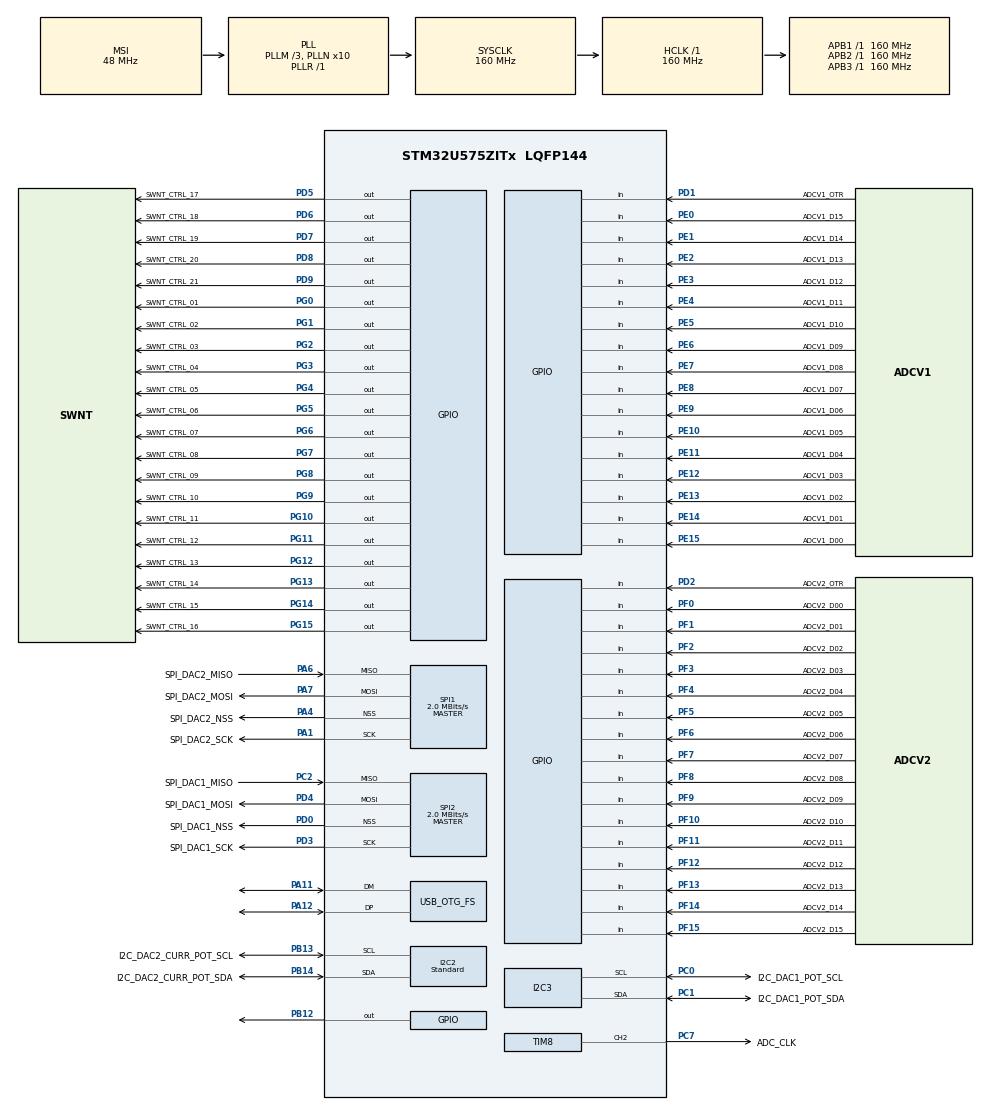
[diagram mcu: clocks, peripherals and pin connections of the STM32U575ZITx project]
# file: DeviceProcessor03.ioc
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CORTEX_M33_NS.userName=CORTEX_M33
GPDMA1.CIRCULARMODE_GPDMACH13=DISABLE
GPDMA1.DESTDATAWIDTH_GPDMACH12=DMA_DEST_DATAWIDTH_HALFWORD
GPDMA1.DESTDATAWIDTH_GPDMACH13=DMA_DEST_DATAWIDTH_HALFWORD
GPDMA1.DESTDATAWIDTH_GPDMACH14=DMA_DEST_DATAWIDTH_HALFWORD
GPDMA1.DESTINC_GPDMACH12=DMA_DINC_INCREMENTED
GPDMA1.DESTINC_GPDMACH13=DMA_DINC_INCREMENTED
GPDMA1.DESTINC_GPDMACH14=DMA_DINC_INCREMENTED
GPDMA1.DIRECTION_GPDMACH12=DMA_PERIPH_TO_MEMORY
GPDMA1.DIRECTION_GPDMACH13=DMA_PERIPH_TO_MEMORY
GPDMA1.DIRECTION_GPDMACH14=DMA_MEMORY_TO_MEMORY
GPDMA1.IPHANDLE_GPDMACH12-SIMPLEREQUEST_GPDMACH12=__NULL
GPDMA1.IPHANDLE_GPDMACH13-SIMPLEREQUEST_GPDMACH13=__NULL
GPDMA1.IPHANDLE_GPDMACH14-SIMPLEREQUEST_GPDMACH14=__NULL
GPDMA1.PRIORITY_GPDMACH12=DMA_LOW_PRIORITY_HIGH_WEIGHT
GPDMA1.PRIORITY_GPDMACH14=DMA_LOW_PRIORITY_HIGH_WEIGHT
GPDMA1.REQUEST_GPDMACH12=GPDMA1_REQUEST_TIM8_UP
GPDMA1.REQUEST_GPDMACH13=GPDMA1_REQUEST_TIM8_UP
GPDMA1.REQUEST_GPDMACH14=GPDMA1_REQUEST_TIM8_UP
GPDMA1.SRCDATAWIDTH_GPDMACH12=DMA_SRC_DATAWIDTH_HALFWORD
GPDMA1.SRCDATAWIDTH_GPDMACH13=DMA_SRC_DATAWIDTH_HALFWORD
GPDMA1.SRCDATAWIDTH_GPDMACH14=DMA_SRC_DATAWIDTH_HALFWORD
GPDMA1.SRCINC_GPDMACH13=DMA_SINC_FIXED
GPDMA1.TRIGGERPOLARITY_GPDMACH12=DMA_TRIG_POLARITY_MASKED
GPDMA1.TRIGGERPOLARITY_GPDMACH13=DMA_TRIG_POLARITY_MASKED
GPDMA1.TRIGGERPOLARITY_GPDMACH14=DMA_TRIG_POLARITY_MASKED
I2C2.I2C_Speed_Mode=I2C_Standard
I2C2.Timing=0x00000E14
I2C3.Timing=0x00000E14
Mcu.Family=STM32U5
Mcu.Name=STM32U575ZITx
Mcu.Package=LQFP144
NVIC.GPDMA1_Channel12_IRQn=true\:0\:0\:false\:false\:true\:false\:true\:true
NVIC.GPDMA1_Channel13_IRQn=true\:0\:0\:false\:false\:true\:false\:true\:true
NVIC.GPDMA1_Channel14_IRQn=true\:0\:0\:false\:false\:true\:false\:true\:true
NVIC.OTG_FS_IRQn=true\:0\:0\:false\:false\:true\:true\:true\:true
NVIC.PriorityGroup=NVIC_PRIORITYGROUP_4
NVIC.TIM8_UP_IRQn=true\:0\:0\:false\:false\:true\:true\:true\:true
PA1.GPIO_Label=SPI_DAC2_SCK
PA1.Mode=Full_Duplex_Master
PA1.Signal=SPI1_SCK
PA11.Mode=Device_Only
PA11.Signal=USB_OTG_FS_DM
PA12.Mode=Device_Only
PA12.Signal=USB_OTG_FS_DP
PA4.GPIO_Label=SPI_DAC2_NSS
PA4.Mode=NSS_Signal_Hard_Output
PA4.Signal=SPI1_NSS
PA6.GPIO_Label=SPI_DAC2_MISO
PA6.Mode=Full_Duplex_Master
PA6.Signal=SPI1_MISO
PA7.GPIO_Label=SPI_DAC2_MOSI
PA7.Mode=Full_Duplex_Master
PA7.Signal=SPI1_MOSI
PB12.Signal=GPIO_Output
PB13.GPIO_Label=I2C_DAC2_CURR_POT_SCL
PB13.GPIO_Pu=GPIO_PULLUP
PB13.GPIO_Speed=GPIO_SPEED_FREQ_VERY_HIGH
PB13.Mode=I2C
PB13.Signal=I2C2_SCL
PB14.GPIO_Label=I2C_DAC2_CURR_POT_SDA
PB14.GPIO_Pu=GPIO_PULLUP
PB14.GPIO_Speed=GPIO_SPEED_FREQ_VERY_HIGH
PB14.Mode=I2C
PB14.Signal=I2C2_SDA
PC0.GPIO_Label=I2C_DAC1_POT_SCL
PC0.GPIO_Pu=GPIO_PULLUP
PC0.GPIO_Speed=GPIO_SPEED_FREQ_VERY_HIGH
PC0.Mode=I2C
PC0.Signal=I2C3_SCL
PC1.GPIO_Label=I2C_DAC1_POT_SDA
PC1.GPIO_Pu=GPIO_PULLUP
PC1.GPIO_Speed=GPIO_SPEED_FREQ_VERY_HIGH
PC1.Mode=I2C
PC1.Signal=I2C3_SDA
PC2.GPIO_Label=SPI_DAC1_MISO
PC2.Mode=Full_Duplex_Master
PC2.Signal=SPI2_MISO
PC7.GPIO_Label=ADC_CLK
PC7.GPIO_Speed=GPIO_SPEED_FREQ_VERY_HIGH
PC7.Signal=S_TIM8_CH2
PD0.GPIO_Label=SPI_DAC1_NSS
PD0.Mode=NSS_Signal_Hard_Output
PD0.Signal=SPI2_NSS
PD1.GPIO_Label=ADCV1_OTR
PD1.Signal=GPIO_Input
PD2.GPIO_Label=ADCV2_OTR
PD2.Signal=GPIO_Input
PD3.GPIO_Label=SPI_DAC1_SCK
PD3.Mode=Full_Duplex_Master
PD3.Signal=SPI2_SCK
PD4.GPIO_Label=SPI_DAC1_MOSI
PD4.Mode=Full_Duplex_Master
PD4.Signal=SPI2_MOSI
PD5.GPIO_Label=SWNT_CTRL_17
PD5.Signal=GPIO_Output
PD6.GPIO_Label=SWNT_CTRL_18
PD6.GPIO_PuPd=GPIO_NOPULL
PD6.Signal=GPIO_Output
PD7.GPIO_Label=SWNT_CTRL_19
PD7.Signal=GPIO_Output
PD8.GPIO_Label=SWNT_CTRL_20
PD8.Signal=GPIO_Output
PD9.GPIO_Label=SWNT_CTRL_21
PD9.Signal=GPIO_Output
PE0.GPIO_Label=ADCV1_D15
PE0.GPIO_PuPd=GPIO_PULLDOWN
PE0.Signal=GPIO_Input
PE1.GPIO_Label=ADCV1_D14
PE1.GPIO_PuPd=GPIO_PULLDOWN
PE1.Signal=GPIO_Input
PE10.GPIO_Label=ADCV1_D05
PE10.Signal=GPIO_Input
PE11.GPIO_Label=ADCV1_D04
PE11.Signal=GPIO_Input
PE12.GPIO_Label=ADCV1_D03
PE12.Signal=GPIO_Input
PE13.GPIO_Label=ADCV1_D02
PE13.Signal=GPIO_Input
PE14.GPIO_Label=ADCV1_D01
PE14.Signal=GPIO_Input
PE15.GPIO_Label=ADCV1_D00
PE15.Signal=GPIO_Input
PE2.GPIO_Label=ADCV1_D13
PE2.GPIO_PuPd=GPIO_PULLDOWN
PE2.Signal=GPIO_Input
PE3.GPIO_Label=ADCV1_D12
PE3.GPIO_PuPd=GPIO_PULLDOWN
PE3.Signal=GPIO_Input
PE4.GPIO_Label=ADCV1_D11
PE4.Signal=GPIO_Input
PE5.GPIO_Label=ADCV1_D10
PE5.Signal=GPIO_Input
PE6.GPIO_Label=ADCV1_D09
PE6.Signal=GPIO_Input
PE7.GPIO_Label=ADCV1_D08
PE7.Signal=GPIO_Input
PE8.GPIO_Label=ADCV1_D07
PE8.Signal=GPIO_Input
PE9.GPIO_Label=ADCV1_D06
PE9.Signal=GPIO_Input
PF0.GPIO_Label=ADCV2_D00
PF0.Signal=GPIO_Input
PF1.GPIO_Label=ADCV2_D01
PF1.Signal=GPIO_Input
PF10.GPIO_Label=ADCV2_D10
PF10.Signal=GPIO_Input
PF11.GPIO_Label=ADCV2_D11
PF11.Signal=GPIO_Input
PF12.GPIO_Label=ADCV2_D12
PF12.GPIO_PuPd=GPIO_PULLDOWN
PF12.Signal=GPIO_Input
PF13.GPIO_Label=ADCV2_D13
PF13.GPIO_PuPd=GPIO_PULLDOWN
PF13.Signal=GPIO_Input
PF14.GPIO_Label=ADCV2_D14
PF14.GPIO_PuPd=GPIO_PULLDOWN
PF14.Signal=GPIO_Input
PF15.GPIO_Label=ADCV2_D15
PF15.GPIO_PuPd=GPIO_PULLDOWN
PF15.Signal=GPIO_Input
PF2.GPIO_Label=ADCV2_D02
PF2.Signal=GPIO_Input
PF3.GPIO_Label=ADCV2_D03
PF3.Signal=GPIO_Input
PF4.GPIO_Label=ADCV2_D04
PF4.Signal=GPIO_Input
PF5.GPIO_Label=ADCV2_D05
PF5.Signal=GPIO_Input
PF6.GPIO_Label=ADCV2_D06
PF6.Signal=GPIO_Input
PF7.GPIO_Label=ADCV2_D07
PF7.Signal=GPIO_Input
PF8.GPIO_Label=ADCV2_D08
PF8.Signal=GPIO_Input
PF9.GPIO_Label=ADCV2_D09
PF9.Signal=GPIO_Input
PG0.GPIO_Label=SWNT_CTRL_01
PG0.Signal=GPIO_Output
PG1.GPIO_Label=SWNT_CTRL_02
PG1.Signal=GPIO_Output
PG10.GPIO_Label=SWNT_CTRL_11
PG10.Signal=GPIO_Output
PG11.GPIO_Label=SWNT_CTRL_12
PG11.Signal=GPIO_Output
PG12.GPIO_Label=SWNT_CTRL_13
PG12.Signal=GPIO_Output
PG13.GPIO_Label=SWNT_CTRL_14
PG13.Signal=GPIO_Output
PG14.GPIO_Label=SWNT_CTRL_15
PG14.Signal=GPIO_Output
PG15.GPIO_Label=SWNT_CTRL_16
PG15.Signal=GPIO_Output
PG2.GPIO_Label=SWNT_CTRL_03
PG2.Signal=GPIO_Output
PG3.GPIO_Label=SWNT_CTRL_04
PG3.Signal=GPIO_Output
PG4.GPIO_Label=SWNT_CTRL_05
PG4.Signal=GPIO_Output
PG5.GPIO_Label=SWNT_CTRL_06
PG5.Signal=GPIO_Output
PG6.GPIO_Label=SWNT_CTRL_07
PG6.Signal=GPIO_Output
PG7.GPIO_Label=SWNT_CTRL_08
PG7.Signal=GPIO_Output
PG8.GPIO_Label=SWNT_CTRL_09
PG8.Signal=GPIO_Output
PG9.GPIO_Label=SWNT_CTRL_10
PG9.Signal=GPIO_Output
ProjectManager.HeapSize=0x200
ProjectManager.StackSize=0x400
ProjectManager.TargetToolchain=STM32CubeIDE
RCC.ADCFreq_Value=16000000
RCC.AHBFreq_Value=160000000
RCC.APB1Freq_Value=160000000
RCC.APB1TimFreq_Value=160000000
RCC.APB2Freq_Value=160000000
RCC.APB2TimFreq_Value=160000000
RCC.APB3Freq_Value=160000000
RCC.CortexFreq_Value=160000000
RCC.EPOD_VALUE=48000000
RCC.HCLKFreq_Value=160000000
RCC.HSE_VALUE=16000000
RCC.HSI48_VALUE=48000000
RCC.HSI_VALUE=16000000
RCC.I2C2CLockSelection=RCC_I2C2CLKSOURCE_MSIK
RCC.I2C3CLockSelection=RCC_I2C3CLKSOURCE_MSIK
RCC.LSE_VALUE=32768
RCC.LSIDIV_VALUE=32000
RCC.MSIClockRange=RCC_MSIRANGE_0
RCC.MSI_VALUE=48000000
RCC.PLL1R=1
RCC.PLL2FRACN=0
RCC.PLL3FRACN=0
RCC.PLLFRACN=0
RCC.PLLM=3
RCC.PLLN=10
RCC.SPI1CLockSelection=RCC_SPI1CLKSOURCE_MSIK
RCC.SPI2CLockSelection=RCC_SPI2CLKSOURCE_MSIK
RCC.SYSCLKFreq_VALUE=160000000
RCC.SYSCLKSource=RCC_SYSCLKSOURCE_PLLCLK
RCC.USBFreq_Value=48000000
RCC.VCOOutputFreq_Value=160000000
SH.S_TIM8_CH2.0=TIM8_CH2,PWM Generation2 CH2
SPI1.CLKPolarity=SPI_POLARITY_HIGH
SPI1.CalculateBaudRate=2.0 MBits/s
SPI1.DataSize=SPI_DATASIZE_8BIT
SPI1.Direction=SPI_DIRECTION_2LINES
SPI1.Mode=SPI_MODE_MASTER
SPI1.VirtualNSS=VM_NSSHARD
SPI1.VirtualType=VM_MASTER
SPI2.CLKPolarity=SPI_POLARITY_HIGH
SPI2.CalculateBaudRate=2.0 MBits/s
SPI2.DataSize=SPI_DATASIZE_8BIT
SPI2.Direction=SPI_DIRECTION_2LINES
SPI2.Mode=SPI_MODE_MASTER
SPI2.VirtualNSS=VM_NSSHARD
SPI2.VirtualType=VM_MASTER
TIM8.AutoReloadPreload=TIM_AUTORELOAD_PRELOAD_ENABLE
TIM8.Channel-PWM\ Generation2\ CH2=TIM_CHANNEL_2
TIM8.PeriodNoDither=15
TIM8.TIM_MasterOutputTrigger=TIM_TRGO_UPDATE
USB_OTG_FS.VirtualMode=Device_Only
VP_GPDMA1_VS_GPDMACH12.Mode=SIMPLEREQUEST_GPDMACH12
VP_GPDMA1_VS_GPDMACH13.Mode=SIMPLEREQUEST_GPDMACH13
VP_GPDMA1_VS_GPDMACH14.Mode=SIMPLEREQUEST_GPDMACH14
VP_ICACHE_VS_ENABLE_ICACHE_MEMORY.Mode=Memoryregions
VP_ICACHE_VS_ICACHE.Mode=DirectMappedCache
VP_LPBAMQUEUE_VS_QUEUE.Mode=QUEUEMODE
VP_LPBAM_VS_SIG1.Mode=SmartRun
VP_LPBAM_VS_SIG4.Mode=LPDMA1
VP_MEMORYMAP_VS_MEMORYMAP.Mode=CurAppReg
VP_PWR_VS_SECSignals.Mode=Security/Privilege
VP_TIM8_VS_ClockSourceINT.Mode=Internal
board=custom

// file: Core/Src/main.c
/* USER CODE BEGIN Header */
/**
  ******************************************************************************
  * @file           : main.c
  * @brief          : Main program body
  ******************************************************************************
  * @attention
  *
  * Copyright (c) 2025 STMicroelectronics.
  * All rights reserved.
  *
  * This software is licensed under terms that can be found in the LICENSE file
  * in the root directory of this software component.
  * If no LICENSE file comes with this software, it is provided AS-IS.
  *
  ******************************************************************************
  */
/* USER CODE END Header */
#include "main.h"

/* USER CODE BEGIN Includes */
#include "usb_device.h"
#include "device_registers.h"
#include "run_device.h"
/* USER CODE END Includes */

DMA_HandleTypeDef handle_GPDMA1_Channel14;
DMA_HandleTypeDef handle_GPDMA1_Channel12;

I2C_HandleTypeDef hi2c2;
I2C_HandleTypeDef hi2c3;

SPI_HandleTypeDef hspi1;
SPI_HandleTypeDef hspi2;

TIM_HandleTypeDef htim8;
DMA_HandleTypeDef handle_GPDMA1_Channel13;

PCD_HandleTypeDef hpcd_USB_OTG_FS;

void SystemClock_Config(void);
static void MX_GPIO_Init(void);
static void MX_GPDMA1_Init(void);
static void MX_USB_OTG_FS_PCD_Init(void);
static void MX_ICACHE_Init(void);
static void MX_TIM8_Init(void);
static void MX_I2C2_Init(void);
static void MX_I2C3_Init(void);
static void MX_SPI2_Init(void);
static void MX_SPI1_Init(void);

/* USER CODE BEGIN 0 */
uint8_t I2C_TX_Buffer1[] = {0,126};
uint8_t I2C_TX_Buffer2[] = {0,15};
uint8_t I2C_TX_Buffer3[] = {0,30};
uint8_t I2C_TX_Buffer4[] = {0,15};
uint8_t SPI_TX_Buffer1[] = {0x21,0x00,0x50,0xC7,0x40,0x00,0xC0,0x00,0x20,0x00};  // 400Hz
uint8_t SPI_TX_Buffer2[] = {0x21,0x00,0x61,0x8E,0x40,0x00,0xC0,0x00,0x20,0x00};  // 800Hz
uint8_t SPI_TX_Buffer3[] = {0x21,0x00,0x63,0x6E,0x40,0x06,0xC0,0x00,0x20,0x00};  // 10kHz
uint8_t SPI_TX_Buffer4[] = {0x21,0x00,0x6B,0x85,0x41,0x47,0xC0,0x00,0x20,0x00};  // 0.5MHz
uint8_t SPI_TX_Buffer5[] = {0x21,0x00,0x59,0x9A,0x46,0x66,0xC0,0x00,0x20,0x00};  // 2.5MHz
uint8_t SPI_TX_Buffer6[] = {0x21,0x00,0x66,0x66,0x59,0x99,0xC0,0x00,0x20,0x00};  // 10MHz
/* USER CODE END 0 */

int main(void)
{

  /* MCU Configuration--------------------------------------------------------*/

  /* Reset of all peripherals, Initializes the Flash interface and the Systick. */
  HAL_Init();

  /* Configure the system clock */
  SystemClock_Config();

  /* Initialize all configured peripherals */
  MX_GPIO_Init();
  MX_GPDMA1_Init();
  MX_USB_OTG_FS_PCD_Init();
  MX_ICACHE_Init();
  MX_TIM8_Init();
  MX_I2C2_Init();
  MX_I2C3_Init();
  MX_SPI2_Init();
  MX_SPI1_Init();
  /* USER CODE BEGIN 2 */
  MX_USB_Device_Init();
  HAL_Delay(2000);
  run_device();
  /* USER CODE END 2 */

  /* Infinite loop */
  while (1)
  {

  }
}

void SystemClock_Config(void)
{
  RCC_OscInitTypeDef RCC_OscInitStruct = {0};
  RCC_ClkInitTypeDef RCC_ClkInitStruct = {0};

  /** Configure the main internal regulator output voltage
  */
  if (HAL_PWREx_ControlVoltageScaling(PWR_REGULATOR_VOLTAGE_SCALE1) != HAL_OK)
  {
    Error_Handler();
  }

  /** Initializes the CPU, AHB and APB buses clocks
  */
  RCC_OscInitStruct.OscillatorType = RCC_OSCILLATORTYPE_HSI48|RCC_OSCILLATORTYPE_MSI
                              |RCC_OSCILLATORTYPE_MSIK;
  RCC_OscInitStruct.HSI48State = RCC_HSI48_ON;
  RCC_OscInitStruct.MSIState = RCC_MSI_ON;
  RCC_OscInitStruct.MSICalibrationValue = RCC_MSICALIBRATION_DEFAULT;
  RCC_OscInitStruct.MSIClockRange = RCC_MSIRANGE_0;
  RCC_OscInitStruct.MSIKClockRange = RCC_MSIKRANGE_4;
  RCC_OscInitStruct.MSIKState = RCC_MSIK_ON;
  RCC_OscInitStruct.PLL.PLLState = RCC_PLL_ON;
  RCC_OscInitStruct.PLL.PLLSource = RCC_PLLSOURCE_MSI;
  RCC_OscInitStruct.PLL.PLLMBOOST = RCC_PLLMBOOST_DIV4;
  RCC_OscInitStruct.PLL.PLLM = 3;
  RCC_OscInitStruct.PLL.PLLN = 10;
  RCC_OscInitStruct.PLL.PLLP = 2;
  RCC_OscInitStruct.PLL.PLLQ = 2;
  RCC_OscInitStruct.PLL.PLLR = 1;
  RCC_OscInitStruct.PLL.PLLRGE = RCC_PLLVCIRANGE_1;
  RCC_OscInitStruct.PLL.PLLFRACN = 0;
  if (HAL_RCC_OscConfig(&RCC_OscInitStruct) != HAL_OK)
  {
    Error_Handler();
  }

  /** Initializes the CPU, AHB and APB buses clocks
  */
  RCC_ClkInitStruct.ClockType = RCC_CLOCKTYPE_HCLK|RCC_CLOCKTYPE_SYSCLK
                              |RCC_CLOCKTYPE_PCLK1|RCC_CLOCKTYPE_PCLK2
                              |RCC_CLOCKTYPE_PCLK3;
  RCC_ClkInitStruct.SYSCLKSource = RCC_SYSCLKSOURCE_PLLCLK;
  RCC_ClkInitStruct.AHBCLKDivider = RCC_SYSCLK_DIV1;
  RCC_ClkInitStruct.APB1CLKDivider = RCC_HCLK_DIV1;
  RCC_ClkInitStruct.APB2CLKDivider = RCC_HCLK_DIV1;
  RCC_ClkInitStruct.APB3CLKDivider = RCC_HCLK_DIV1;

  if (HAL_RCC_ClockConfig(&RCC_ClkInitStruct, FLASH_LATENCY_4) != HAL_OK)
  {
    Error_Handler();
  }
}

static void MX_GPDMA1_Init(void)
{

  /* Peripheral clock enable */
  __HAL_RCC_GPDMA1_CLK_ENABLE();

  /* GPDMA1 interrupt Init */
    HAL_NVIC_SetPriority(GPDMA1_Channel13_IRQn, 0, 0);
    HAL_NVIC_EnableIRQ(GPDMA1_Channel13_IRQn);

  handle_GPDMA1_Channel14.Instance = GPDMA1_Channel14;
  handle_GPDMA1_Channel14.Init.Request = DMA_REQUEST_SW;
  handle_GPDMA1_Channel14.Init.BlkHWRequest = DMA_BREQ_SINGLE_BURST;
  handle_GPDMA1_Channel14.Init.Direction = DMA_MEMORY_TO_MEMORY;
  handle_GPDMA1_Channel14.Init.SrcInc = DMA_SINC_FIXED;
  handle_GPDMA1_Channel14.Init.DestInc = DMA_DINC_FIXED;
  handle_GPDMA1_Channel14.Init.SrcDataWidth = DMA_SRC_DATAWIDTH_BYTE;
  handle_GPDMA1_Channel14.Init.DestDataWidth = DMA_DEST_DATAWIDTH_BYTE;
  handle_GPDMA1_Channel14.Init.Priority = DMA_LOW_PRIORITY_LOW_WEIGHT;
  handle_GPDMA1_Channel14.Init.SrcBurstLength = 1;
  handle_GPDMA1_Channel14.Init.DestBurstLength = 1;
  handle_GPDMA1_Channel14.Init.TransferAllocatedPort = DMA_SRC_ALLOCATED_PORT0|DMA_DEST_ALLOCATED_PORT0;
  handle_GPDMA1_Channel14.Init.TransferEventMode = DMA_TCEM_BLOCK_TRANSFER;
  handle_GPDMA1_Channel14.Init.Mode = DMA_NORMAL;
  if (HAL_DMA_Init(&handle_GPDMA1_Channel14) != HAL_OK)
  {
    Error_Handler();
  }
  if (HAL_DMA_ConfigChannelAttributes(&handle_GPDMA1_Channel14, DMA_CHANNEL_NPRIV) != HAL_OK)
  {
    Error_Handler();
  }
  handle_GPDMA1_Channel12.Instance = GPDMA1_Channel12;
  handle_GPDMA1_Channel12.Init.Request = DMA_REQUEST_SW;
  handle_GPDMA1_Channel12.Init.BlkHWRequest = DMA_BREQ_SINGLE_BURST;
  handle_GPDMA1_Channel12.Init.Direction = DMA_MEMORY_TO_MEMORY;
  handle_GPDMA1_Channel12.Init.SrcInc = DMA_SINC_FIXED;
  handle_GPDMA1_Channel12.Init.DestInc = DMA_DINC_FIXED;
  handle_GPDMA1_Channel12.Init.SrcDataWidth = DMA_SRC_DATAWIDTH_BYTE;
  handle_GPDMA1_Channel12.Init.DestDataWidth = DMA_DEST_DATAWIDTH_BYTE;
  handle_GPDMA1_Channel12.Init.Priority = DMA_LOW_PRIORITY_LOW_WEIGHT;
  handle_GPDMA1_Channel12.Init.SrcBurstLength = 1;
  handle_GPDMA1_Channel12.Init.DestBurstLength = 1;
  handle_GPDMA1_Channel12.Init.TransferAllocatedPort = DMA_SRC_ALLOCATED_PORT0|DMA_DEST_ALLOCATED_PORT0;
  handle_GPDMA1_Channel12.Init.TransferEventMode = DMA_TCEM_BLOCK_TRANSFER;
  handle_GPDMA1_Channel12.Init.Mode = DMA_NORMAL;
  if (HAL_DMA_Init(&handle_GPDMA1_Channel12) != HAL_OK)
  {
    Error_Handler();
  }
  if (HAL_DMA_ConfigChannelAttributes(&handle_GPDMA1_Channel12, DMA_CHANNEL_NPRIV) != HAL_OK)
  {
    Error_Handler();
  }

}

static void MX_I2C2_Init(void)
{

  hi2c2.Instance = I2C2;
  hi2c2.Init.Timing = 0x00000E14;
  hi2c2.Init.OwnAddress1 = 0;
  hi2c2.Init.AddressingMode = I2C_ADDRESSINGMODE_7BIT;
  hi2c2.Init.DualAddressMode = I2C_DUALADDRESS_DISABLE;
  hi2c2.Init.OwnAddress2 = 0;
  hi2c2.Init.OwnAddress2Masks = I2C_OA2_NOMASK;
  hi2c2.Init.GeneralCallMode = I2C_GENERALCALL_DISABLE;
  hi2c2.Init.NoStretchMode = I2C_NOSTRETCH_DISABLE;
  if (HAL_I2C_Init(&hi2c2) != HAL_OK)
  {
    Error_Handler();
  }

  /** Configure Analogue filter
  */
  if (HAL_I2CEx_ConfigAnalogFilter(&hi2c2, I2C_ANALOGFILTER_ENABLE) != HAL_OK)
  {
    Error_Handler();
  }

  /** Configure Digital filter
  */
  if (HAL_I2CEx_ConfigDigitalFilter(&hi2c2, 0) != HAL_OK)
  {
    Error_Handler();
  }

}

static void MX_I2C3_Init(void)
{

  hi2c3.Instance = I2C3;
  hi2c3.Init.Timing = 0x00000E14;
  hi2c3.Init.OwnAddress1 = 0;
  hi2c3.Init.AddressingMode = I2C_ADDRESSINGMODE_7BIT;
  hi2c3.Init.DualAddressMode = I2C_DUALADDRESS_DISABLE;
  hi2c3.Init.OwnAddress2 = 0;
  hi2c3.Init.OwnAddress2Masks = I2C_OA2_NOMASK;
  hi2c3.Init.GeneralCallMode = I2C_GENERALCALL_DISABLE;
  hi2c3.Init.NoStretchMode = I2C_NOSTRETCH_DISABLE;
  if (HAL_I2C_Init(&hi2c3) != HAL_OK)
  {
    Error_Handler();
  }

  /** Configure Analogue filter
  */
  if (HAL_I2CEx_ConfigAnalogFilter(&hi2c3, I2C_ANALOGFILTER_ENABLE) != HAL_OK)
  {
    Error_Handler();
  }

  /** Configure Digital filter
  */
  if (HAL_I2CEx_ConfigDigitalFilter(&hi2c3, 0) != HAL_OK)
  {
    Error_Handler();
  }

}

static void MX_ICACHE_Init(void)
{

  /** Enable instruction cache in 1-way (direct mapped cache)
  */
  if (HAL_ICACHE_ConfigAssociativityMode(ICACHE_1WAY) != HAL_OK)
  {
    Error_Handler();
  }
  if (HAL_ICACHE_Enable() != HAL_OK)
  {
    Error_Handler();
  }

}

static void MX_SPI1_Init(void)
{

  SPI_AutonomousModeConfTypeDef HAL_SPI_AutonomousMode_Cfg_Struct = {0};

  /* SPI1 parameter configuration*/
  hspi1.Instance = SPI1;
  hspi1.Init.Mode = SPI_MODE_MASTER;
  hspi1.Init.Direction = SPI_DIRECTION_2LINES;
  hspi1.Init.DataSize = SPI_DATASIZE_8BIT;
  hspi1.Init.CLKPolarity = SPI_POLARITY_HIGH;
  hspi1.Init.CLKPhase = SPI_PHASE_1EDGE;
  hspi1.Init.NSS = SPI_NSS_HARD_OUTPUT;
  hspi1.Init.BaudRatePrescaler = SPI_BAUDRATEPRESCALER_2;
  hspi1.Init.FirstBit = SPI_FIRSTBIT_MSB;
  hspi1.Init.TIMode = SPI_TIMODE_DISABLE;
  hspi1.Init.CRCCalculation = SPI_CRCCALCULATION_DISABLE;
  hspi1.Init.CRCPolynomial = 0x7;
  hspi1.Init.NSSPMode = SPI_NSS_PULSE_ENABLE;
  hspi1.Init.NSSPolarity = SPI_NSS_POLARITY_LOW;
  hspi1.Init.FifoThreshold = SPI_FIFO_THRESHOLD_01DATA;
  hspi1.Init.MasterSSIdleness = SPI_MASTER_SS_IDLENESS_00CYCLE;
  hspi1.Init.MasterInterDataIdleness = SPI_MASTER_INTERDATA_IDLENESS_00CYCLE;
  hspi1.Init.MasterReceiverAutoSusp = SPI_MASTER_RX_AUTOSUSP_DISABLE;
  hspi1.Init.MasterKeepIOState = SPI_MASTER_KEEP_IO_STATE_DISABLE;
  hspi1.Init.IOSwap = SPI_IO_SWAP_DISABLE;
  hspi1.Init.ReadyMasterManagement = SPI_RDY_MASTER_MANAGEMENT_INTERNALLY;
  hspi1.Init.ReadyPolarity = SPI_RDY_POLARITY_HIGH;
  if (HAL_SPI_Init(&hspi1) != HAL_OK)
  {
    Error_Handler();
  }
  HAL_SPI_AutonomousMode_Cfg_Struct.TriggerState = SPI_AUTO_MODE_DISABLE;
  HAL_SPI_AutonomousMode_Cfg_Struct.TriggerSelection = SPI_GRP1_GPDMA_CH0_TCF_TRG;
  HAL_SPI_AutonomousMode_Cfg_Struct.TriggerPolarity = SPI_TRIG_POLARITY_RISING;
  if (HAL_SPIEx_SetConfigAutonomousMode(&hspi1, &HAL_SPI_AutonomousMode_Cfg_Struct) != HAL_OK)
  {
    Error_Handler();
  }

}

static void MX_SPI2_Init(void)
{

  SPI_AutonomousModeConfTypeDef HAL_SPI_AutonomousMode_Cfg_Struct = {0};

  /* SPI2 parameter configuration*/
  hspi2.Instance = SPI2;
  hspi2.Init.Mode = SPI_MODE_MASTER;
  hspi2.Init.Direction = SPI_DIRECTION_2LINES;
  hspi2.Init.DataSize = SPI_DATASIZE_8BIT;
  hspi2.Init.CLKPolarity = SPI_POLARITY_HIGH;
  hspi2.Init.CLKPhase = SPI_PHASE_1EDGE;
  hspi2.Init.NSS = SPI_NSS_HARD_OUTPUT;
  hspi2.Init.BaudRatePrescaler = SPI_BAUDRATEPRESCALER_2;
  hspi2.Init.FirstBit = SPI_FIRSTBIT_MSB;
  hspi2.Init.TIMode = SPI_TIMODE_DISABLE;
  hspi2.Init.CRCCalculation = SPI_CRCCALCULATION_DISABLE;
  hspi2.Init.CRCPolynomial = 0x7;
  hspi2.Init.NSSPMode = SPI_NSS_PULSE_ENABLE;
  hspi2.Init.NSSPolarity = SPI_NSS_POLARITY_LOW;
  hspi2.Init.FifoThreshold = SPI_FIFO_THRESHOLD_01DATA;
  hspi2.Init.MasterSSIdleness = SPI_MASTER_SS_IDLENESS_00CYCLE;
  hspi2.Init.MasterInterDataIdleness = SPI_MASTER_INTERDATA_IDLENESS_00CYCLE;
  hspi2.Init.MasterReceiverAutoSusp = SPI_MASTER_RX_AUTOSUSP_DISABLE;
  hspi2.Init.MasterKeepIOState = SPI_MASTER_KEEP_IO_STATE_DISABLE;
  hspi2.Init.IOSwap = SPI_IO_SWAP_DISABLE;
  hspi2.Init.ReadyMasterManagement = SPI_RDY_MASTER_MANAGEMENT_INTERNALLY;
  hspi2.Init.ReadyPolarity = SPI_RDY_POLARITY_HIGH;
  if (HAL_SPI_Init(&hspi2) != HAL_OK)
  {
    Error_Handler();
  }
  HAL_SPI_AutonomousMode_Cfg_Struct.TriggerState = SPI_AUTO_MODE_DISABLE;
  HAL_SPI_AutonomousMode_Cfg_Struct.TriggerSelection = SPI_GRP1_GPDMA_CH0_TCF_TRG;
  HAL_SPI_AutonomousMode_Cfg_Struct.TriggerPolarity = SPI_TRIG_POLARITY_RISING;
  if (HAL_SPIEx_SetConfigAutonomousMode(&hspi2, &HAL_SPI_AutonomousMode_Cfg_Struct) != HAL_OK)
  {
    Error_Handler();
  }

}

static void MX_TIM8_Init(void)
{

  TIM_ClockConfigTypeDef sClockSourceConfig = {0};
  TIM_MasterConfigTypeDef sMasterConfig = {0};
  TIM_OC_InitTypeDef sConfigOC = {0};
  TIM_BreakDeadTimeConfigTypeDef sBreakDeadTimeConfig = {0};

  htim8.Instance = TIM8;
  htim8.Init.Prescaler = 0;
  htim8.Init.CounterMode = TIM_COUNTERMODE_UP;
  htim8.Init.Period = 65535;
  htim8.Init.ClockDivision = TIM_CLOCKDIVISION_DIV1;
  htim8.Init.RepetitionCounter = 0;
  htim8.Init.AutoReloadPreload = TIM_AUTORELOAD_PRELOAD_ENABLE;
  if (HAL_TIM_Base_Init(&htim8) != HAL_OK)
  {
    Error_Handler();
  }
  sClockSourceConfig.ClockSource = TIM_CLOCKSOURCE_INTERNAL;
  if (HAL_TIM_ConfigClockSource(&htim8, &sClockSourceConfig) != HAL_OK)
  {
    Error_Handler();
  }
  if (HAL_TIM_PWM_Init(&htim8) != HAL_OK)
  {
    Error_Handler();
  }
  sMasterConfig.MasterOutputTrigger = TIM_TRGO_UPDATE;
  sMasterConfig.MasterOutputTrigger2 = TIM_TRGO2_RESET;
  sMasterConfig.MasterSlaveMode = TIM_MASTERSLAVEMODE_DISABLE;
  if (HAL_TIMEx_MasterConfigSynchronization(&htim8, &sMasterConfig) != HAL_OK)
  {
    Error_Handler();
  }
  sConfigOC.OCMode = TIM_OCMODE_PWM1;
  sConfigOC.Pulse = 0;
  sConfigOC.OCPolarity = TIM_OCPOLARITY_HIGH;
  sConfigOC.OCNPolarity = TIM_OCNPOLARITY_HIGH;
  sConfigOC.OCFastMode = TIM_OCFAST_DISABLE;
  sConfigOC.OCIdleState = TIM_OCIDLESTATE_RESET;
  sConfigOC.OCNIdleState = TIM_OCNIDLESTATE_RESET;
  if (HAL_TIM_PWM_ConfigChannel(&htim8, &sConfigOC, TIM_CHANNEL_2) != HAL_OK)
  {
    Error_Handler();
  }
  sBreakDeadTimeConfig.OffStateRunMode = TIM_OSSR_DISABLE;
  sBreakDeadTimeConfig.OffStateIDLEMode = TIM_OSSI_DISABLE;
  sBreakDeadTimeConfig.LockLevel = TIM_LOCKLEVEL_OFF;
  sBreakDeadTimeConfig.DeadTime = 0;
  sBreakDeadTimeConfig.BreakState = TIM_BREAK_DISABLE;
  sBreakDeadTimeConfig.BreakPolarity = TIM_BREAKPOLARITY_HIGH;
  sBreakDeadTimeConfig.BreakFilter = 0;
  sBreakDeadTimeConfig.BreakAFMode = TIM_BREAK_AFMODE_INPUT;
  sBreakDeadTimeConfig.Break2State = TIM_BREAK2_DISABLE;
  sBreakDeadTimeConfig.Break2Polarity = TIM_BREAK2POLARITY_HIGH;
  sBreakDeadTimeConfig.Break2Filter = 0;
  sBreakDeadTimeConfig.Break2AFMode = TIM_BREAK_AFMODE_INPUT;
  sBreakDeadTimeConfig.AutomaticOutput = TIM_AUTOMATICOUTPUT_DISABLE;
  if (HAL_TIMEx_ConfigBreakDeadTime(&htim8, &sBreakDeadTimeConfig) != HAL_OK)
  {
    Error_Handler();
  }
  HAL_TIM_MspPostInit(&htim8);

}

static void MX_USB_OTG_FS_PCD_Init(void)
{

  hpcd_USB_OTG_FS.Instance = USB_OTG_FS;
  hpcd_USB_OTG_FS.Init.dev_endpoints = 6;
  hpcd_USB_OTG_FS.Init.speed = PCD_SPEED_FULL;
  hpcd_USB_OTG_FS.Init.phy_itface = PCD_PHY_EMBEDDED;
  hpcd_USB_OTG_FS.Init.Sof_enable = DISABLE;
  hpcd_USB_OTG_FS.Init.low_power_enable = DISABLE;
  hpcd_USB_OTG_FS.Init.lpm_enable = DISABLE;
  hpcd_USB_OTG_FS.Init.battery_charging_enable = DISABLE;
  hpcd_USB_OTG_FS.Init.use_dedicated_ep1 = DISABLE;
  hpcd_USB_OTG_FS.Init.vbus_sensing_enable = DISABLE;
  hpcd_USB_OTG_FS.Init.dma_enable = DISABLE;
  if (HAL_PCD_Init(&hpcd_USB_OTG_FS) != HAL_OK)
  {
    Error_Handler();
  }

}

static void MX_GPIO_Init(void)
{
  GPIO_InitTypeDef GPIO_InitStruct = {0};

  /* GPIO Ports Clock Enable */
  __HAL_RCC_GPIOE_CLK_ENABLE();
  __HAL_RCC_GPIOF_CLK_ENABLE();
  __HAL_RCC_GPIOC_CLK_ENABLE();
  __HAL_RCC_GPIOA_CLK_ENABLE();
  __HAL_RCC_GPIOG_CLK_ENABLE();
  __HAL_RCC_GPIOB_CLK_ENABLE();
  __HAL_RCC_GPIOD_CLK_ENABLE();

  /*Configure GPIO pin Output Level */
  HAL_GPIO_WritePin(GPIOG, SWNT_CTRL_01_Pin|SWNT_CTRL_02_Pin|SWNT_CTRL_03_Pin|SWNT_CTRL_04_Pin
                          |SWNT_CTRL_05_Pin|SWNT_CTRL_06_Pin|SWNT_CTRL_07_Pin|SWNT_CTRL_08_Pin
                          |SWNT_CTRL_09_Pin|SWNT_CTRL_10_Pin|SWNT_CTRL_11_Pin|SWNT_CTRL_12_Pin
                          |SWNT_CTRL_13_Pin|SWNT_CTRL_14_Pin|SWNT_CTRL_15_Pin|SWNT_CTRL_16_Pin, GPIO_PIN_RESET);

  /*Configure GPIO pin Output Level */
  HAL_GPIO_WritePin(GPIOD, SWNT_CTRL_20_Pin|SWNT_CTRL_21_Pin|SWNT_CTRL_17_Pin|SWNT_CTRL_18_Pin
                          |SWNT_CTRL_19_Pin, GPIO_PIN_RESET);

  /*Configure GPIO pins : ADCV1_D13_Pin ADCV1_D12_Pin ADCV1_D11_Pin ADCV1_D10_Pin
                           ADCV1_D09_Pin ADCV1_D08_Pin ADCV1_D07_Pin ADCV1_D06_Pin
                           ADCV1_D05_Pin ADCV1_D04_Pin ADCV1_D03_Pin ADCV1_D02_Pin
                           ADCV1_D01_Pin ADCV1_D00_Pin ADCV1_D15_Pin ADCV1_D14_Pin */
  GPIO_InitStruct.Pin = ADCV1_D13_Pin|ADCV1_D12_Pin|ADCV1_D11_Pin|ADCV1_D10_Pin
                          |ADCV1_D09_Pin|ADCV1_D08_Pin|ADCV1_D07_Pin|ADCV1_D06_Pin
                          |ADCV1_D05_Pin|ADCV1_D04_Pin|ADCV1_D03_Pin|ADCV1_D02_Pin
                          |ADCV1_D01_Pin|ADCV1_D00_Pin|ADCV1_D15_Pin|ADCV1_D14_Pin;
  GPIO_InitStruct.Mode = GPIO_MODE_INPUT;
  GPIO_InitStruct.Pull = GPIO_NOPULL;
  HAL_GPIO_Init(GPIOE, &GPIO_InitStruct);

  /*Configure GPIO pins : ADCV2_D00_Pin ADCV2_D01_Pin ADCV2_D02_Pin ADCV2_D03_Pin
                           ADCV2_D04_Pin ADCV2_D05_Pin ADCV2_D06_Pin ADCV2_D07_Pin
                           ADCV2_D08_Pin ADCV2_D09_Pin ADCV2_D10_Pin ADCV2_D11_Pin */
  GPIO_InitStruct.Pin = ADCV2_D00_Pin|ADCV2_D01_Pin|ADCV2_D02_Pin|ADCV2_D03_Pin
                          |ADCV2_D04_Pin|ADCV2_D05_Pin|ADCV2_D06_Pin|ADCV2_D07_Pin
                          |ADCV2_D08_Pin|ADCV2_D09_Pin|ADCV2_D10_Pin|ADCV2_D11_Pin;
  GPIO_InitStruct.Mode = GPIO_MODE_INPUT;
  GPIO_InitStruct.Pull = GPIO_NOPULL;
  HAL_GPIO_Init(GPIOF, &GPIO_InitStruct);

  /*Configure GPIO pins : ADCV2_D12_Pin ADCV2_D13_Pin ADCV2_D14_Pin ADCV2_D15_Pin */
  GPIO_InitStruct.Pin = ADCV2_D12_Pin|ADCV2_D13_Pin|ADCV2_D14_Pin|ADCV2_D15_Pin;
  GPIO_InitStruct.Mode = GPIO_MODE_INPUT;
  GPIO_InitStruct.Pull = GPIO_PULLDOWN;
  HAL_GPIO_Init(GPIOF, &GPIO_InitStruct);

  /*Configure GPIO pins : SWNT_CTRL_01_Pin SWNT_CTRL_02_Pin SWNT_CTRL_03_Pin SWNT_CTRL_04_Pin
                           SWNT_CTRL_05_Pin SWNT_CTRL_06_Pin SWNT_CTRL_07_Pin SWNT_CTRL_08_Pin
                           SWNT_CTRL_09_Pin SWNT_CTRL_10_Pin SWNT_CTRL_11_Pin SWNT_CTRL_12_Pin
                           SWNT_CTRL_13_Pin SWNT_CTRL_14_Pin SWNT_CTRL_15_Pin SWNT_CTRL_16_Pin */
  GPIO_InitStruct.Pin = SWNT_CTRL_01_Pin|SWNT_CTRL_02_Pin|SWNT_CTRL_03_Pin|SWNT_CTRL_04_Pin
                          |SWNT_CTRL_05_Pin|SWNT_CTRL_06_Pin|SWNT_CTRL_07_Pin|SWNT_CTRL_08_Pin
                          |SWNT_CTRL_09_Pin|SWNT_CTRL_10_Pin|SWNT_CTRL_11_Pin|SWNT_CTRL_12_Pin
                          |SWNT_CTRL_13_Pin|SWNT_CTRL_14_Pin|SWNT_CTRL_15_Pin|SWNT_CTRL_16_Pin;
  GPIO_InitStruct.Mode = GPIO_MODE_OUTPUT_PP;
  GPIO_InitStruct.Pull = GPIO_NOPULL;
  GPIO_InitStruct.Speed = GPIO_SPEED_FREQ_LOW;
  HAL_GPIO_Init(GPIOG, &GPIO_InitStruct);

  /*Configure GPIO pins : SWNT_CTRL_20_Pin SWNT_CTRL_21_Pin SWNT_CTRL_17_Pin SWNT_CTRL_18_Pin
                           SWNT_CTRL_19_Pin */
  GPIO_InitStruct.Pin = SWNT_CTRL_20_Pin|SWNT_CTRL_21_Pin|SWNT_CTRL_17_Pin|SWNT_CTRL_18_Pin
                          |SWNT_CTRL_19_Pin;
  GPIO_InitStruct.Mode = GPIO_MODE_OUTPUT_PP;
  GPIO_InitStruct.Pull = GPIO_NOPULL;
  GPIO_InitStruct.Speed = GPIO_SPEED_FREQ_LOW;
  HAL_GPIO_Init(GPIOD, &GPIO_InitStruct);

  /*Configure GPIO pins : ADCV1_OTR_Pin ADCV2_OTR_Pin */
  GPIO_InitStruct.Pin = ADCV1_OTR_Pin|ADCV2_OTR_Pin;
  GPIO_InitStruct.Mode = GPIO_MODE_INPUT;
  GPIO_InitStruct.Pull = GPIO_NOPULL;
  HAL_GPIO_Init(GPIOD, &GPIO_InitStruct);

}

void Error_Handler(void)
{
  __disable_irq();
  while (1)
  {
  }
}
